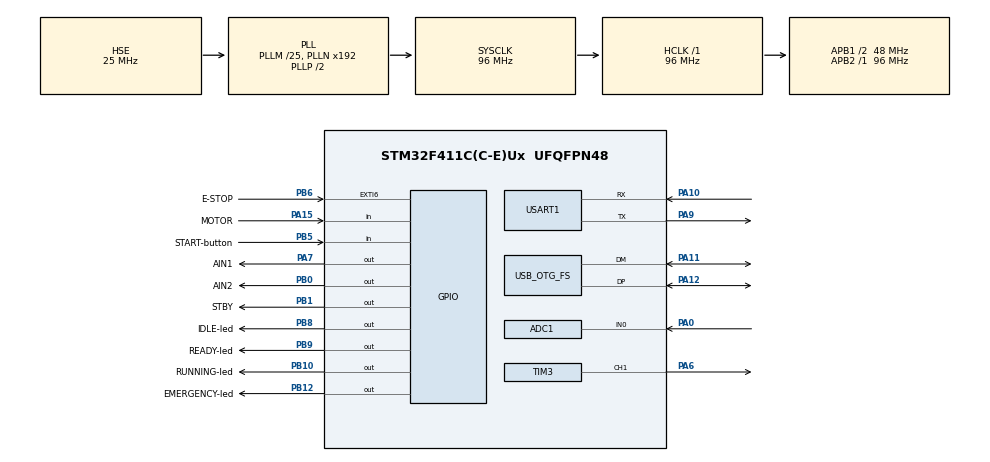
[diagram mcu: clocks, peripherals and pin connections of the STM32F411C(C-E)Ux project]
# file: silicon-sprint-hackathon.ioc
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ADC1.Channel-0\#ChannelRegularConversion=ADC_CHANNEL_0
ADC1.Channel-1\#ChannelInjectedConversion=ADC_CHANNEL_0
ADC1.InjNumberOfConversion=1
ADC1.InjectedOffset-1\#ChannelInjectedConversion=0
ADC1.InjectedRank-1\#ChannelInjectedConversion=1
ADC1.NbrOfConversionFlag=1
ADC1.Rank-0\#ChannelRegularConversion=1
ADC1.SamplingTime-0\#ChannelRegularConversion=ADC_SAMPLETIME_3CYCLES
ADC1.SamplingTime-1\#ChannelInjectedConversion=ADC_SAMPLETIME_3CYCLES
ADC1.master=1
Mcu.Family=STM32F4
Mcu.Name=STM32F411C(C-E)Ux
Mcu.Package=UFQFPN48
NVIC.EXTI9_5_IRQn=true\:0\:0\:true\:false\:true\:true\:true\:true
NVIC.OTG_FS_IRQn=true\:0\:0\:false\:false\:true\:false\:true\:true
NVIC.PriorityGroup=NVIC_PRIORITYGROUP_4
NVIC.USART1_IRQn=true\:1\:0\:true\:false\:true\:true\:true\:true
PA0-WKUP.Signal=ADCx_IN0
PA10.Mode=Asynchronous
PA10.Signal=USART1_RX
PA11.Mode=Device_Only
PA11.Signal=USB_OTG_FS_DM
PA12.Mode=Device_Only
PA12.Signal=USB_OTG_FS_DP
PA15.GPIO_Label=MOTOR
PA15.GPIO_PuPd=GPIO_PULLUP
PA15.Signal=GPIO_Input
PA6.Signal=S_TIM3_CH1
PA7.GPIO_Label=AIN1
PA7.GPIO_PuPd=GPIO_PULLUP
PA7.Signal=GPIO_Output
PA9.Mode=Asynchronous
PA9.Signal=USART1_TX
PB0.GPIO_Label=AIN2
PB0.GPIO_PuPd=GPIO_PULLUP
PB0.Signal=GPIO_Output
PB1.GPIO_Label=STBY
PB1.GPIO_PuPd=GPIO_PULLUP
PB1.Signal=GPIO_Output
PB10.GPIO_Label=RUNNING-led
PB10.Signal=GPIO_Output
PB12.GPIO_Label=EMERGENCY-led
PB12.Signal=GPIO_Output
PB5.GPIO_Label=START-button
PB5.GPIO_PuPd=GPIO_PULLUP
PB5.Signal=GPIO_Input
PB6.GPIO_Label=E-STOP
PB6.GPIO_ModeDefaultEXTI=GPIO_MODE_IT_FALLING
PB6.GPIO_PuPd=GPIO_PULLUP
PB6.Signal=GPXTI6
PB8.GPIO_Label=IDLE-led
PB8.Signal=GPIO_Output
PB9.GPIO_Label=READY-led
PB9.Signal=GPIO_Output
PH0\ -\ OSC_IN.Mode=HSE-External-Oscillator
PH0\ -\ OSC_IN.Signal=RCC_OSC_IN
PH1\ -\ OSC_OUT.Mode=HSE-External-Oscillator
PH1\ -\ OSC_OUT.Signal=RCC_OSC_OUT
ProjectManager.HeapSize=0x200
ProjectManager.StackSize=0x400
ProjectManager.TargetToolchain=STM32CubeIDE
RCC.48MHZClocksFreq_Value=48000000
RCC.AHBFreq_Value=96000000
RCC.APB1CLKDivider=RCC_HCLK_DIV2
RCC.APB1Freq_Value=48000000
RCC.APB1TimFreq_Value=96000000
RCC.APB2Freq_Value=96000000
RCC.APB2TimFreq_Value=96000000
RCC.CortexFreq_Value=96000000
RCC.HCLKFreq_Value=96000000
RCC.PLLM=25
RCC.SYSCLKFreq_VALUE=96000000
RCC.SYSCLKSource=RCC_SYSCLKSOURCE_PLLCLK
RCC.VCOOutputFreq_Value=192000000
SH.ADCx_IN0.0=ADC1_IN0,IN0
SH.S_TIM3_CH1.0=TIM3_CH1,PWM Generation1 CH1
TIM3.Channel-PWM\ Generation1\ CH1=TIM_CHANNEL_1
TIM3.Period=799
TIM3.Prescaler=0
USART1.VirtualMode=VM_ASYNC
USB_DEVICE.CLASS_NAME_FS=CDC
USB_DEVICE.VirtualMode=Cdc
USB_DEVICE.VirtualModeFS=Cdc_FS
USB_OTG_FS.VirtualMode=Device_Only
VP_USB_DEVICE_VS_USB_DEVICE_CDC_FS.Mode=CDC_FS
board=custom

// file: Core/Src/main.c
/* USER CODE BEGIN Header */
/**
  ******************************************************************************
  * @file           : main.c
  * @brief          : Main program body
  ******************************************************************************
  * @attention
  *
  * Copyright (c) 2026 STMicroelectronics.
  * All rights reserved.
  *
  * This software is licensed under terms that can be found in the LICENSE file
  * in the root directory of this software component.
  * If no LICENSE file comes with this software, it is provided AS-IS.
  *
  ******************************************************************************
  */
/* USER CODE END Header */
#include "main.h"
#include "usb_device.h"

/* USER CODE BEGIN Includes */
#include "app.h"
/* USER CODE END Includes */

ADC_HandleTypeDef hadc1;

TIM_HandleTypeDef htim3;

UART_HandleTypeDef huart1;

void SystemClock_Config(void);
static void MX_GPIO_Init(void);
static void MX_ADC1_Init(void);
static void MX_TIM3_Init(void);
static void MX_USART1_UART_Init(void);

int main(void)
{

  /* USER CODE BEGIN 1 */
	App_Run();
  /* USER CODE END 1 */

  /* MCU Configuration--------------------------------------------------------*/

  /* Reset of all peripherals, Initializes the Flash interface and the Systick. */
  HAL_Init();

  /* Configure the system clock */
  SystemClock_Config();

  /* Initialize all configured peripherals */
  MX_GPIO_Init();
  MX_ADC1_Init();
  MX_TIM3_Init();
  MX_USART1_UART_Init();
  MX_USB_DEVICE_Init();
  /* USER CODE BEGIN 2 */
  App_Init();
  /* USER CODE END 2 */

  /* Infinite loop */
  while (1)
  {
		App_Run();
  }
}

void SystemClock_Config(void)
{
  RCC_OscInitTypeDef RCC_OscInitStruct = {0};
  RCC_ClkInitTypeDef RCC_ClkInitStruct = {0};

  /** Configure the main internal regulator output voltage
  */
  __HAL_RCC_PWR_CLK_ENABLE();
  __HAL_PWR_VOLTAGESCALING_CONFIG(PWR_REGULATOR_VOLTAGE_SCALE1);

  /** Initializes the RCC Oscillators according to the specified parameters
  * in the RCC_OscInitTypeDef structure.
  */
  RCC_OscInitStruct.OscillatorType = RCC_OSCILLATORTYPE_HSE;
  RCC_OscInitStruct.HSEState = RCC_HSE_ON;
  RCC_OscInitStruct.PLL.PLLState = RCC_PLL_ON;
  RCC_OscInitStruct.PLL.PLLSource = RCC_PLLSOURCE_HSE;
  RCC_OscInitStruct.PLL.PLLM = 25;
  RCC_OscInitStruct.PLL.PLLN = 192;
  RCC_OscInitStruct.PLL.PLLP = RCC_PLLP_DIV2;
  RCC_OscInitStruct.PLL.PLLQ = 4;
  if (HAL_RCC_OscConfig(&RCC_OscInitStruct) != HAL_OK)
  {
    Error_Handler();
  }

  /** Initializes the CPU, AHB and APB buses clocks
  */
  RCC_ClkInitStruct.ClockType = RCC_CLOCKTYPE_HCLK|RCC_CLOCKTYPE_SYSCLK
                              |RCC_CLOCKTYPE_PCLK1|RCC_CLOCKTYPE_PCLK2;
  RCC_ClkInitStruct.SYSCLKSource = RCC_SYSCLKSOURCE_PLLCLK;
  RCC_ClkInitStruct.AHBCLKDivider = RCC_SYSCLK_DIV1;
  RCC_ClkInitStruct.APB1CLKDivider = RCC_HCLK_DIV2;
  RCC_ClkInitStruct.APB2CLKDivider = RCC_HCLK_DIV1;

  if (HAL_RCC_ClockConfig(&RCC_ClkInitStruct, FLASH_LATENCY_3) != HAL_OK)
  {
    Error_Handler();
  }
}

static void MX_ADC1_Init(void)
{

  ADC_ChannelConfTypeDef sConfig = {0};
  ADC_InjectionConfTypeDef sConfigInjected = {0};

  /** Configure the global features of the ADC (Clock, Resolution, Data Alignment and number of conversion)
  */
  hadc1.Instance = ADC1;
  hadc1.Init.ClockPrescaler = ADC_CLOCK_SYNC_PCLK_DIV4;
  hadc1.Init.Resolution = ADC_RESOLUTION_12B;
  hadc1.Init.ScanConvMode = DISABLE;
  hadc1.Init.ContinuousConvMode = DISABLE;
  hadc1.Init.DiscontinuousConvMode = DISABLE;
  hadc1.Init.ExternalTrigConvEdge = ADC_EXTERNALTRIGCONVEDGE_NONE;
  hadc1.Init.ExternalTrigConv = ADC_SOFTWARE_START;
  hadc1.Init.DataAlign = ADC_DATAALIGN_RIGHT;
  hadc1.Init.NbrOfConversion = 1;
  hadc1.Init.DMAContinuousRequests = DISABLE;
  hadc1.Init.EOCSelection = ADC_EOC_SINGLE_CONV;
  if (HAL_ADC_Init(&hadc1) != HAL_OK)
  {
    Error_Handler();
  }

  /** Configure for the selected ADC regular channel its corresponding rank in the sequencer and its sample time.
  */
  sConfig.Channel = ADC_CHANNEL_0;
  sConfig.Rank = 1;
  sConfig.SamplingTime = ADC_SAMPLETIME_3CYCLES;
  if (HAL_ADC_ConfigChannel(&hadc1, &sConfig) != HAL_OK)
  {
    Error_Handler();
  }

  /** Configures for the selected ADC injected channel its corresponding rank in the sequencer and its sample time
  */
  sConfigInjected.InjectedChannel = ADC_CHANNEL_0;
  sConfigInjected.InjectedRank = 1;
  sConfigInjected.InjectedNbrOfConversion = 1;
  sConfigInjected.InjectedSamplingTime = ADC_SAMPLETIME_3CYCLES;
  sConfigInjected.ExternalTrigInjecConvEdge = ADC_EXTERNALTRIGINJECCONVEDGE_NONE;
  sConfigInjected.ExternalTrigInjecConv = ADC_INJECTED_SOFTWARE_START;
  sConfigInjected.AutoInjectedConv = DISABLE;
  sConfigInjected.InjectedDiscontinuousConvMode = DISABLE;
  sConfigInjected.InjectedOffset = 0;
  if (HAL_ADCEx_InjectedConfigChannel(&hadc1, &sConfigInjected) != HAL_OK)
  {
    Error_Handler();
  }

}

static void MX_TIM3_Init(void)
{

  TIM_MasterConfigTypeDef sMasterConfig = {0};
  TIM_OC_InitTypeDef sConfigOC = {0};

  htim3.Instance = TIM3;
  htim3.Init.Prescaler = 0;
  htim3.Init.CounterMode = TIM_COUNTERMODE_UP;
  htim3.Init.Period = 799;
  htim3.Init.ClockDivision = TIM_CLOCKDIVISION_DIV1;
  htim3.Init.AutoReloadPreload = TIM_AUTORELOAD_PRELOAD_DISABLE;
  if (HAL_TIM_PWM_Init(&htim3) != HAL_OK)
  {
    Error_Handler();
  }
  sMasterConfig.MasterOutputTrigger = TIM_TRGO_RESET;
  sMasterConfig.MasterSlaveMode = TIM_MASTERSLAVEMODE_DISABLE;
  if (HAL_TIMEx_MasterConfigSynchronization(&htim3, &sMasterConfig) != HAL_OK)
  {
    Error_Handler();
  }
  sConfigOC.OCMode = TIM_OCMODE_PWM1;
  sConfigOC.Pulse = 0;
  sConfigOC.OCPolarity = TIM_OCPOLARITY_HIGH;
  sConfigOC.OCFastMode = TIM_OCFAST_DISABLE;
  if (HAL_TIM_PWM_ConfigChannel(&htim3, &sConfigOC, TIM_CHANNEL_1) != HAL_OK)
  {
    Error_Handler();
  }
  HAL_TIM_MspPostInit(&htim3);

}

static void MX_USART1_UART_Init(void)
{

  huart1.Instance = USART1;
  huart1.Init.BaudRate = 115200;
  huart1.Init.WordLength = UART_WORDLENGTH_8B;
  huart1.Init.StopBits = UART_STOPBITS_1;
  huart1.Init.Parity = UART_PARITY_NONE;
  huart1.Init.Mode = UART_MODE_TX_RX;
  huart1.Init.HwFlowCtl = UART_HWCONTROL_NONE;
  huart1.Init.OverSampling = UART_OVERSAMPLING_16;
  if (HAL_UART_Init(&huart1) != HAL_OK)
  {
    Error_Handler();
  }

}

static void MX_GPIO_Init(void)
{
  GPIO_InitTypeDef GPIO_InitStruct = {0};

  /* GPIO Ports Clock Enable */
  __HAL_RCC_GPIOH_CLK_ENABLE();
  __HAL_RCC_GPIOA_CLK_ENABLE();
  __HAL_RCC_GPIOB_CLK_ENABLE();

  /*Configure GPIO pin Output Level */
  HAL_GPIO_WritePin(AIN1_GPIO_Port, AIN1_Pin, GPIO_PIN_RESET);

  /*Configure GPIO pin Output Level */
  HAL_GPIO_WritePin(GPIOB, AIN2_Pin|STBY_Pin|RUNNING_led_Pin|EMERGENCY_led_Pin
                          |IDLE_led_Pin|READY_led_Pin, GPIO_PIN_RESET);

  /*Configure GPIO pin : AIN1_Pin */
  GPIO_InitStruct.Pin = AIN1_Pin;
  GPIO_InitStruct.Mode = GPIO_MODE_OUTPUT_PP;
  GPIO_InitStruct.Pull = GPIO_PULLUP;
  GPIO_InitStruct.Speed = GPIO_SPEED_FREQ_LOW;
  HAL_GPIO_Init(AIN1_GPIO_Port, &GPIO_InitStruct);

  /*Configure GPIO pins : AIN2_Pin STBY_Pin */
  GPIO_InitStruct.Pin = AIN2_Pin|STBY_Pin;
  GPIO_InitStruct.Mode = GPIO_MODE_OUTPUT_PP;
  GPIO_InitStruct.Pull = GPIO_PULLUP;
  GPIO_InitStruct.Speed = GPIO_SPEED_FREQ_LOW;
  HAL_GPIO_Init(GPIOB, &GPIO_InitStruct);

  /*Configure GPIO pins : RUNNING_led_Pin EMERGENCY_led_Pin IDLE_led_Pin READY_led_Pin */
  GPIO_InitStruct.Pin = RUNNING_led_Pin|EMERGENCY_led_Pin|IDLE_led_Pin|READY_led_Pin;
  GPIO_InitStruct.Mode = GPIO_MODE_OUTPUT_PP;
  GPIO_InitStruct.Pull = GPIO_NOPULL;
  GPIO_InitStruct.Speed = GPIO_SPEED_FREQ_LOW;
  HAL_GPIO_Init(GPIOB, &GPIO_InitStruct);

  /*Configure GPIO pin : MOTOR_Pin */
  GPIO_InitStruct.Pin = MOTOR_Pin;
  GPIO_InitStruct.Mode = GPIO_MODE_INPUT;
  GPIO_InitStruct.Pull = GPIO_PULLUP;
  HAL_GPIO_Init(MOTOR_GPIO_Port, &GPIO_InitStruct);

  /*Configure GPIO pin : START_button_Pin */
  GPIO_InitStruct.Pin = START_button_Pin;
  GPIO_InitStruct.Mode = GPIO_MODE_INPUT;
  GPIO_InitStruct.Pull = GPIO_PULLUP;
  HAL_GPIO_Init(START_button_GPIO_Port, &GPIO_InitStruct);

  /*Configure GPIO pin : E_STOP_Pin */
  GPIO_InitStruct.Pin = E_STOP_Pin;
  GPIO_InitStruct.Mode = GPIO_MODE_IT_FALLING;
  GPIO_InitStruct.Pull = GPIO_PULLUP;
  HAL_GPIO_Init(E_STOP_GPIO_Port, &GPIO_InitStruct);

  /* EXTI interrupt init*/
  HAL_NVIC_SetPriority(EXTI9_5_IRQn, 0, 0);
  HAL_NVIC_EnableIRQ(EXTI9_5_IRQn);

}

void Error_Handler(void)
{
  __disable_irq();
  while (1)
  {
  }
}
